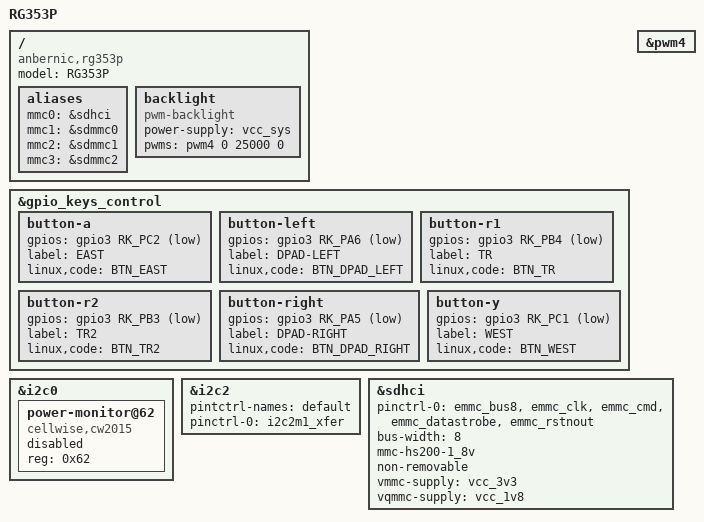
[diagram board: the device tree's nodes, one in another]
// SPDX-License-Identifier: (GPL-2.0+ OR MIT)

/dts-v1/;

#include <dt-bindings/gpio/gpio.h>
#include <dt-bindings/input/linux-event-codes.h>
#include <dt-bindings/pinctrl/rockchip.h>
#include "rk3566-anbernic-rgxx3.dtsi"

/ {
	model = "RG353P";
	compatible = "anbernic,rg353p", "rockchip,rk3566";

	aliases {
		mmc0 = &sdhci;
		mmc1 = &sdmmc0;
		mmc2 = &sdmmc1;
		mmc3 = &sdmmc2;
	};

	backlight: backlight {
		compatible = "pwm-backlight";
		power-supply = <&vcc_sys>;
		pwms = <&pwm4 0 25000 0>;
	};
};

&gpio_keys_control {
	button-a {
		gpios = <&gpio3 RK_PC2 GPIO_ACTIVE_LOW>;
		label = "EAST";
		linux,code = <BTN_EAST>;
	};

	button-left {
		gpios = <&gpio3 RK_PA6 GPIO_ACTIVE_LOW>;
		label = "DPAD-LEFT";
		linux,code = <BTN_DPAD_LEFT>;
	};

	button-r1 {
		gpios = <&gpio3 RK_PB4 GPIO_ACTIVE_LOW>;
		label = "TR";
		linux,code = <BTN_TR>;
	};

	button-r2 {
		gpios = <&gpio3 RK_PB3 GPIO_ACTIVE_LOW>;
		label = "TR2";
		linux,code = <BTN_TR2>;
	};

	button-right {
		gpios = <&gpio3 RK_PA5 GPIO_ACTIVE_LOW>;
		label = "DPAD-RIGHT";
		linux,code = <BTN_DPAD_RIGHT>;
	};

	button-y {
		gpios = <&gpio3 RK_PC1 GPIO_ACTIVE_LOW>;
		label = "WEST";
		linux,code = <BTN_WEST>;
	};
};

&i2c0 {
	/* This hardware is physically present but unused. */
	power-monitor@62 {
		compatible = "cellwise,cw2015";
		reg = <0x62>;
		status = "disabled";
	};
};

&i2c2 {
	pintctrl-names = "default";
	pinctrl-0 = <&i2c2m1_xfer>;
	status = "okay";
};

&pwm4 {
	status = "okay";
};

&sdhci {
	pinctrl-0 = <&emmc_bus8>, <&emmc_clk>, <&emmc_cmd>, <&emmc_datastrobe>, <&emmc_rstnout>;
	pinctrl-names = "default";
	bus-width = <8>;
	mmc-hs200-1_8v;
	non-removable;
	vmmc-supply = <&vcc_3v3>;
	vqmmc-supply = <&vcc_1v8>;
	status = "okay";
};
